# PIC32MX170F512H device description
Architecture: MIPS; Family: PIC32MX; Series: PIC32MX
Registers are 32-bit, read-write, no defined reset value unless marked. A register's access mark holds for its fields unless they carry their own. Offsets are from the block's base; [hi:lo] are bit positions; {n}, {i} and the like mark numbered series.

## PMP
Instances: PMP 0x1f807000 in periph0
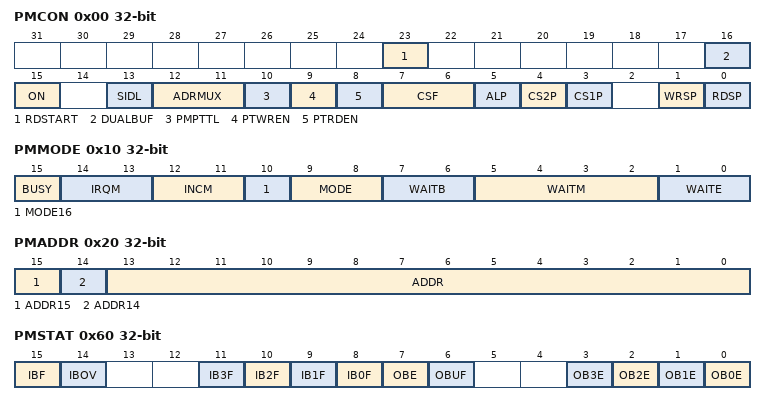
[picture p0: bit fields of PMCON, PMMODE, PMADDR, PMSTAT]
0x00 PMCON — Parallel Port Control Register
  [23] RDSTART — Start Read on PMP Bus bit
    1=Start a read cycle on the PMP bus; 0=No effect
  [16] DUALBUF — Dual Read/Write Buffers enable bit
    2=PMP uses separate registers for reads and writes; 0=PMP uses legacy registers
  [15] ON — Parallel Master Port Enable bit
    1=PMP is enabled; 0=PMP is disabled
  [13] SIDL — Stop in Idle Mode bit
    1=Discontinue module operation when device enters Idle mode; 0=Continue module operation in Idle mode
  [12:11] ADRMUX — Address/Data Multiplexing Selection bits
    3=Lower 8 bits of address are multiplexed on PMD pins; upper 8 bits are not used; 2=All 16 bits of address are multiplexed on PMD pins; 1=Lower 8 bits of address are multiplexed on PMD pins; 0=Address and data appear on separate pins
  [10] PMPTTL — PMP Module TTL Input Buffer Select bit
    1=PMP module uses TTL input buffers; 0=PMP module uses Schmitt Trigger input buffer
  [9] PTWREN — Write Enable Strobe Port Enable bit
    1=PMWR/PMENB port is enabled; 0=PMWR/PMENB port is disabled
  [8] PTRDEN — Read/Write Strobe Port Enable bit
    1=PMRD/PMWR port is enabled; 0=PMRD/PMWR port is disabled
  [7:6] CSF — Chip Select Function bits
    2=PMCS1 and PMCS2 function as Chip Select; 1=PMCS2 functions as Chip Select and PMCS1 functions as address bit 14; 0=PMCS1 and PMCS2 function as address bit 14 and address bit 15
  [5] ALP — Address Latch Polarity bit
    1=Active-high (PMALL and PMALH); 0=Active-low (PMALL and PMALH)
  [4] CS2P — Chip Select 2 Polarity bit
    1=Active-high (PMCS2); 0=Active-low (PMCS2)
  [3] CS1P — Chip Select 1 Polarity bit
    1=Active-high (PMCS1); 0=Active-low (PMCS1)
  [1] WRSP — Write Strobe Polarity bit
    1=(Slave and Master mode 2) Write strobe active-high / (Master mode 1) Enable strobe active-high; 0=(Slave and Master mode 2) Write strobe active-low / (Master mode 1) Enable strobe active-low
  [0] RDSP — Read Strobe Polarity bit
    1=(Slave and Master mode 2) Read Strobe active-high / (Master mode 1) Read/write strobe active-high; 0=(Slave and Master mode 2) Read Strobe active-low / (Master mode 1) Read/write strobe active-low
0x10 PMMODE — Parallel Port Mode Register
  [15] BUSY — Busy bit
    1=Port is busy; 0=Port is not busy
  [14:13] IRQM — Interrupt Request Mode bits
    2=Interrupt is generated when Read Buffer 3 is read or Write Buffer 3 is written (Buffered PSP mode)or on a read or write operation when PMA = 11 (Addressable Slave mode only); 1=Interrupt is generated at the end of the read/write cycle; 0=No Interrupt is generated
  [12:11] INCM — Increment Mode bits
    3=Slave mode read and write buffers auto-increment (MODE(1-0) = 00 only); 2=Decrement ADDR(15-0) by 1 every read/write cycle; 1=Increment ADDR(15-0) by 1 every read/write cycle; 0=No increment or decrement of address
  [10] MODE16 — 8/16-bit Mode bit
    1=16-bit mode: a read or write to the data register invokes a single 16-bit transfer; 0=8-bit mode: a read or write to the data register invokes a single 8-bit transfer
  [9:8] MODE
    3=Master mode 1; 2=Master mode 2; 1=Enhanced Slave mode, control signals; 0=Legacy Parallel Slave Port, control signals
  [7:6] WAITB — Data Setup to Read/Write Strobe Wait States bits
    {v}=Data wait of {v+1} Tpbclk2 (v=0..3)
  [5:2] WAITM — Data Read/Write Strobe Wait States bits
    15=Wait of 16 Tpbclk2; 1=Wait of 2 Tpbclk2; 0=Wait of 1 Tpbclk2 (default)
  [1:0] WAITE — Data Hold After Read/Write Strobe Wait States bits
    3=(for writes) Wait of 4 Tpbclk2 / (for reads) Wait of 3 Tpbclk2; 2=(for writes) Wait of 3 Tpbclk2 / (for reads) Wait of 2 Tpbclk2; 1=(for writes) Wait of 2 Tpbclk2 / (for reads) Wait of 1 Tpbclk2; 0=(for writes) Wait of 1 Tpbclk2 (default) / (for reads) Wait of 0 Tpbclk2 (default)
0x20 PMADDR — Parallel Port Address Register
  [15] ADDR15 — Target Address bit 15
    0=Address bit15 is 0
  [14] ADDR14 — Target Address bit 14
    0=Address bit14 is 0
  [13:0] ADDR — Address bits
    0=Address is 0
0x30 PMDOUT — Parallel Port Output Data Register
  [31:0] DATAOUT — Port Data Output bits
    0=Data output is 0
0x40 PMDIN — Parallel Port Input Data Register
  [31:0] DATAIN — Port Data Input bits
    0=Data input is 0
0x50 PMAEN — Parallel Port Pin Enable Register
  [23:0] PTEN — PMALH/PMALL Strobe Enable bits
    0x4000=PMA15 and PMA14 function as either PMA or PMCS1 and PMCS2; 0=PMA15 and PMA14 function as port I/O; 4=PMA function as PMP address lines; 0=PMA function as port I/O; 1=PMA1 and PMA0 function as either PMA or PMALH and PMALL; 0=PMA1 and PMA0 pads function as port I/O
0x60 PMSTAT — Parallel Port Status Register (Slave modes only)
  [15] IBF — Input Buffer Full Status bit
    1=All writable input buffer registers are full; 0=Some or all of the writable input buffer registers are empty
  [14] IBOV — Input Buffer Overflow Status bit
    1=A write attempt to a full input byte buffer is occurred (must be cleared in software); 0=No overflow is occurred
  [n+8] IB{n}F (n=0..3) — Input Buffer {n} Status Full bit
    1=Input Buffer contains data that has not been read (reading buffer will clear this bit); 0=Input Buffer does not contain any unread data
  [7] OBE — Output Buffer Empty Status bit
    1=All readable output buffer registers are empty; 0=Some or all of the readable output buffer registers are full
  [6] OBUF — Output Buffer Underflow Status bit
    1=A read occurred from an empty output byte buffer (must be cleared in software); 0=No underflow is occurred
  [n] OB{n}E (n=0..3) — Output Buffer {n} Status Empty bit
    1=Output buffer is empty (writing data to the buffer will clear this bit); 0=Output buffer contains data that has not been transmitted
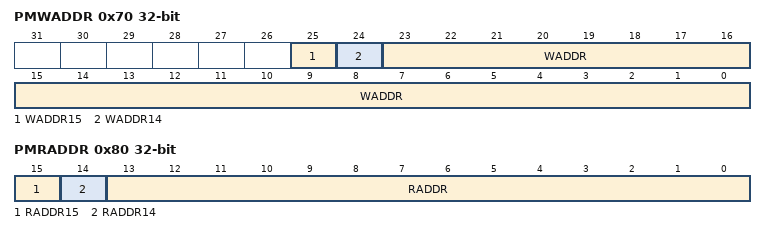
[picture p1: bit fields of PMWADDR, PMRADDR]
0x70 PMWADDR — Parallel Port Write Address Register
  [25] WADDR15 — Target Address bit 15
    0=Bit15 is 0
  [24] WADDR14 — Target Address bit 14
    0=Bit14 is 0
  [23:0] WADDR — Address bits
    0=Write address is 0
0x80 PMRADDR — Parallel Port Read Address Register
  [15] RADDR15, [14] RADDR14, [13:0] RADDR
0x90 PMRDIN — Parallel Port Read Input Data Register
  [31:0] RDATAIN
Value list PMADDR__CS1: 1=Chip Select 1 is active; 0=Chip Select 1 is inactive
Value list PMADDR__CS2: 1=Chip Select 2 is active; 0=Chip Select 2 is inactive
Value list PMRADDR__RCS1: 1=Chip Select 1 is active; 0=Chip Select 1 is inactive (RADDR14 function is selected)
Value list PMRADDR__RCS2: 1=Chip Select 2 is active; 0=Chip Select 2 is inactive (RADDR15 function is selected)
